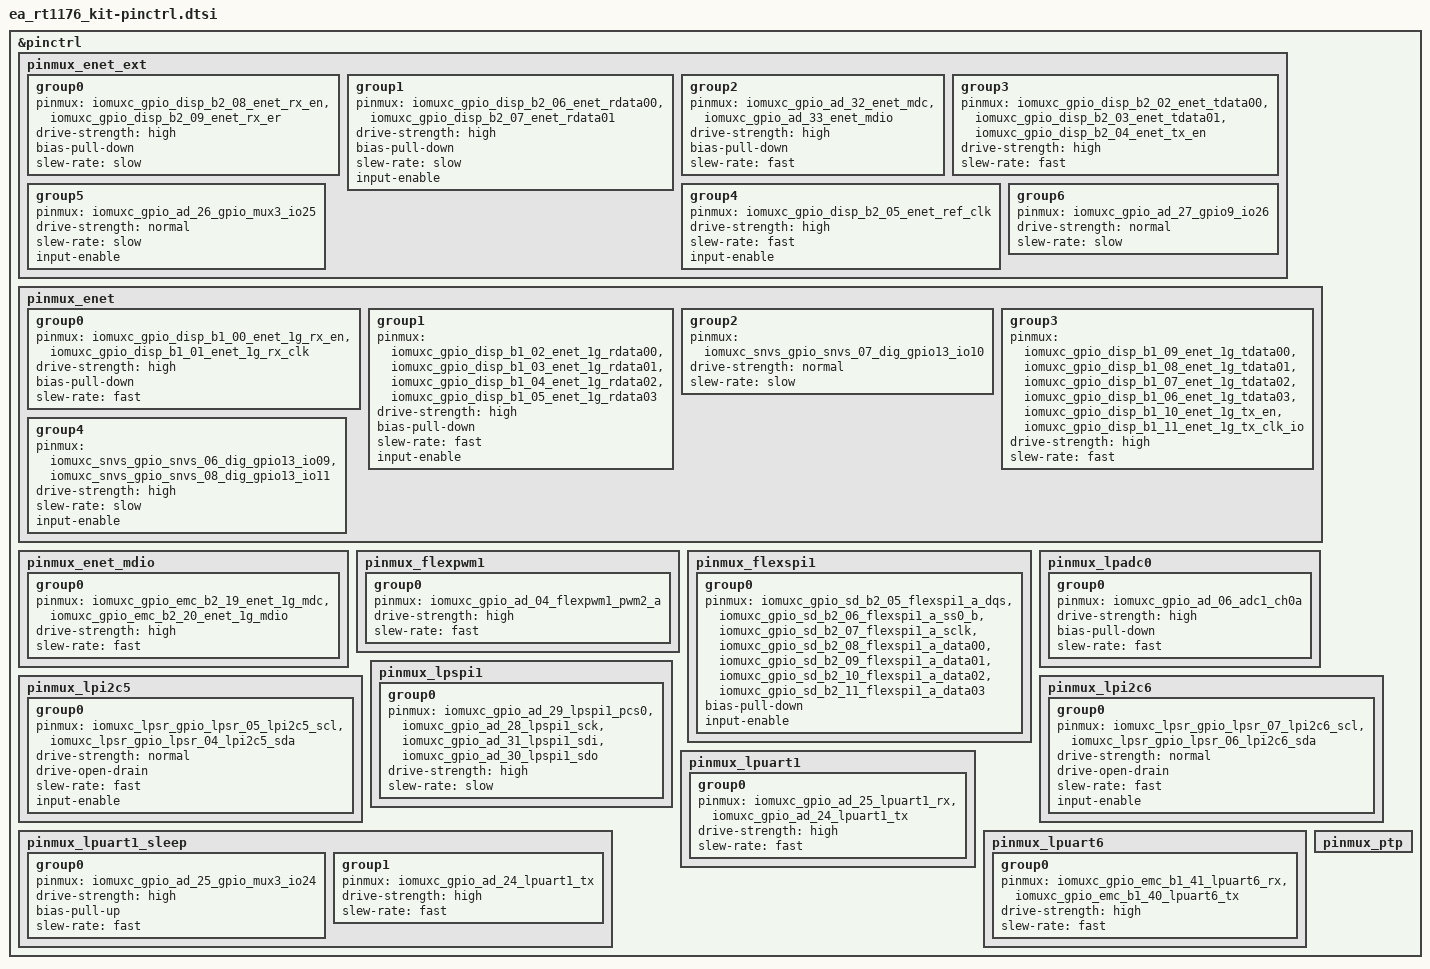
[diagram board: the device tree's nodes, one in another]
/*
 * Copyright (c) 2024, Embedded Artists
 * SPDX-License-Identifier: Apache-2.0
 *
 * Note: File generated by rt_cfg_utils.py
 * from mimxrt1170_evk.mex
 */

#include <nxp/nxp_imx/rt/mimxrt1176cvm8a-pinctrl.dtsi>

&pinctrl {

	pinmux_enet_ext: pinmux_enet_ext {
		group0 {
			pinmux = <&iomuxc_gpio_disp_b2_08_enet_rx_en>,
				<&iomuxc_gpio_disp_b2_09_enet_rx_er>;
			drive-strength = "high";
			bias-pull-down;
			slew-rate = "slow";
		};
		group1 {
			pinmux = <&iomuxc_gpio_disp_b2_06_enet_rdata00>,
				<&iomuxc_gpio_disp_b2_07_enet_rdata01>;
			drive-strength = "high";
			bias-pull-down;
			slew-rate = "slow";
			input-enable;
		};
		group2 {
			pinmux = <&iomuxc_gpio_ad_32_enet_mdc>,
				<&iomuxc_gpio_ad_33_enet_mdio>;
			drive-strength = "high";
			bias-pull-down;
			slew-rate = "fast";
		};
		group3 {
			pinmux = <&iomuxc_gpio_disp_b2_02_enet_tdata00>,
				<&iomuxc_gpio_disp_b2_03_enet_tdata01>,
				<&iomuxc_gpio_disp_b2_04_enet_tx_en>;
			drive-strength = "high";
			slew-rate = "fast";
		};
		group4 {
			pinmux = <&iomuxc_gpio_disp_b2_05_enet_ref_clk>;
			drive-strength = "high";
			slew-rate = "fast";
			input-enable;
		};
		group5 {
			pinmux = <&iomuxc_gpio_ad_26_gpio_mux3_io25>;
			drive-strength = "normal";
			slew-rate = "slow";
			input-enable;
		};
		group6 {
			pinmux = <&iomuxc_gpio_ad_27_gpio9_io26>;
			drive-strength = "normal";
			slew-rate = "slow";
		};
	};

	pinmux_enet: pinmux_enet {
		group0 {
			pinmux = <&iomuxc_gpio_disp_b1_00_enet_1g_rx_en>,
				<&iomuxc_gpio_disp_b1_01_enet_1g_rx_clk>;
			drive-strength = "high";
			bias-pull-down;
			slew-rate = "fast";
		};
		group1 {
			pinmux = <&iomuxc_gpio_disp_b1_02_enet_1g_rdata00>,
				<&iomuxc_gpio_disp_b1_03_enet_1g_rdata01>,
				<&iomuxc_gpio_disp_b1_04_enet_1g_rdata02>,
				<&iomuxc_gpio_disp_b1_05_enet_1g_rdata03>;
			drive-strength = "high";
			bias-pull-down;
			slew-rate = "fast";
			input-enable;
		};
		group2 {
			pinmux = <&iomuxc_snvs_gpio_snvs_07_dig_gpio13_io10>;
			drive-strength = "normal";
			slew-rate = "slow";
		};
		group3 {
			pinmux = <&iomuxc_gpio_disp_b1_09_enet_1g_tdata00>,
				<&iomuxc_gpio_disp_b1_08_enet_1g_tdata01>,
				<&iomuxc_gpio_disp_b1_07_enet_1g_tdata02>,
				<&iomuxc_gpio_disp_b1_06_enet_1g_tdata03>,
				<&iomuxc_gpio_disp_b1_10_enet_1g_tx_en>,
				<&iomuxc_gpio_disp_b1_11_enet_1g_tx_clk_io>;
			drive-strength = "high";
			slew-rate = "fast";
		};
		group4 {
			pinmux = <&iomuxc_snvs_gpio_snvs_06_dig_gpio13_io09>,
				<&iomuxc_snvs_gpio_snvs_08_dig_gpio13_io11>;
			drive-strength = "high";
			slew-rate = "slow";
			input-enable;
		};
	};

	pinmux_enet_mdio: pinmux_enet_mdio {
		group0 {
			pinmux = <&iomuxc_gpio_emc_b2_19_enet_1g_mdc>,
				<&iomuxc_gpio_emc_b2_20_enet_1g_mdio>;
			drive-strength = "high";
			slew-rate = "fast";
		};
	};

	pinmux_flexpwm1: pinmux_flexpwm1 {
		group0 {
			pinmux = <&iomuxc_gpio_ad_04_flexpwm1_pwm2_a>;
			drive-strength = "high";
			slew-rate = "fast";
		};
	};

	pinmux_flexspi1: pinmux_flexspi1 {
		group0 {
			pinmux = <&iomuxc_gpio_sd_b2_05_flexspi1_a_dqs>,
				<&iomuxc_gpio_sd_b2_06_flexspi1_a_ss0_b>,
				<&iomuxc_gpio_sd_b2_07_flexspi1_a_sclk>,
				<&iomuxc_gpio_sd_b2_08_flexspi1_a_data00>,
				<&iomuxc_gpio_sd_b2_09_flexspi1_a_data01>,
				<&iomuxc_gpio_sd_b2_10_flexspi1_a_data02>,
				<&iomuxc_gpio_sd_b2_11_flexspi1_a_data03>;
			bias-pull-down;
			input-enable;
		};
	};

	pinmux_lpadc0: pinmux_lpadc0 {
		group0 {
			pinmux = <&iomuxc_gpio_ad_06_adc1_ch0a>;
			drive-strength = "high";
			bias-pull-down;
			slew-rate = "fast";
		};
	};

	pinmux_lpi2c5: pinmux_lpi2c5 {
		group0 {
			pinmux = <&iomuxc_lpsr_gpio_lpsr_05_lpi2c5_scl>,
				<&iomuxc_lpsr_gpio_lpsr_04_lpi2c5_sda>;
			drive-strength = "normal";
			drive-open-drain;
			slew-rate = "fast";
			input-enable;
		};
	};

	pinmux_lpi2c6: pinmux_lpi2c6 {
		group0 {
			pinmux = <&iomuxc_lpsr_gpio_lpsr_07_lpi2c6_scl>,
				<&iomuxc_lpsr_gpio_lpsr_06_lpi2c6_sda>;
			drive-strength = "normal";
			drive-open-drain;
			slew-rate = "fast";
			input-enable;
		};
	};

	pinmux_lpspi1: pinmux_lpspi1 {
		group0 {
			pinmux = <&iomuxc_gpio_ad_29_lpspi1_pcs0>,
				<&iomuxc_gpio_ad_28_lpspi1_sck>,
				<&iomuxc_gpio_ad_31_lpspi1_sdi>,
				<&iomuxc_gpio_ad_30_lpspi1_sdo>;
			drive-strength = "high";
			slew-rate = "slow";
		};
	};

	pinmux_lpuart1: pinmux_lpuart1 {
		group0 {
			pinmux = <&iomuxc_gpio_ad_25_lpuart1_rx>,
				<&iomuxc_gpio_ad_24_lpuart1_tx>;
			drive-strength = "high";
			slew-rate = "fast";
		};
	};

	pinmux_lpuart1_sleep: pinmux_lpuart1_sleep {
		group0 {
			pinmux = <&iomuxc_gpio_ad_25_gpio_mux3_io24>;
			drive-strength = "high";
			bias-pull-up;
			slew-rate = "fast";
		};
		group1 {
			pinmux = <&iomuxc_gpio_ad_24_lpuart1_tx>;
			drive-strength = "high";
			slew-rate = "fast";
		};
	};

	pinmux_lpuart6: pinmux_lpuart6 {
		group0 {
			pinmux = <&iomuxc_gpio_emc_b1_41_lpuart6_rx>,
				<&iomuxc_gpio_emc_b1_40_lpuart6_tx>;
			drive-strength = "high";
			slew-rate = "fast";
		};
	};

	/* intentionally left empty */
	pinmux_ptp: pinmux_ptp {
	};
};

